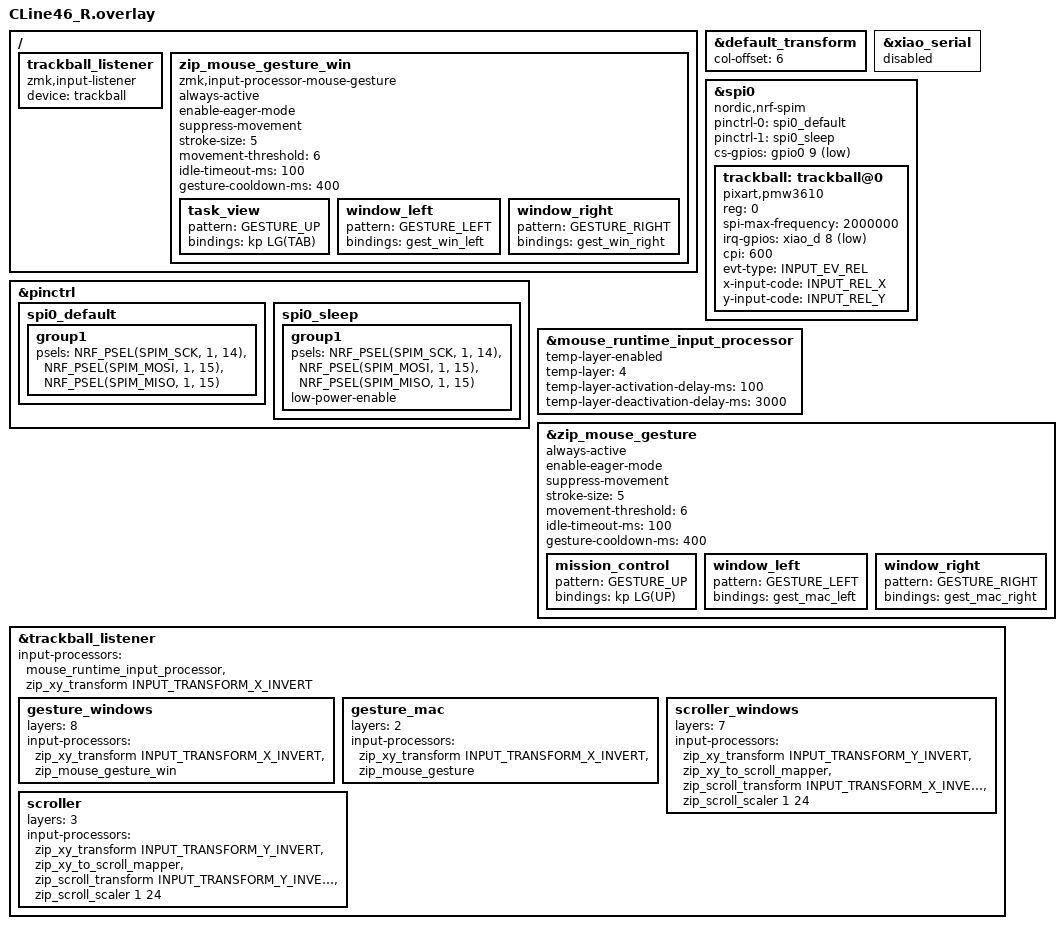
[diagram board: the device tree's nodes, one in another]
#include "CLine46.dtsi"
#include <zephyr/dt-bindings/input/input-event-codes.h>
#include <input/processors.dtsi>
#include <input/processors/runtime-input-processor.dtsi>
#include <behaviors/battery_history_request.dtsi>
#include <mouse-gesture.dtsi>
#include <dt-bindings/zmk/mouse-gesture.h>
#include <dt-bindings/zmk/keys.h>

&default_transform {
    col-offset = <6>;
};


/ {
    trackball_listener {
        status = "okay";
        compatible = "zmk,input-listener";
        device = <&trackball>;
    };
};

&pinctrl {
    spi0_default: spi0_default {
        group1 {
            psels = <NRF_PSEL(SPIM_SCK, 1, 14)>,
                <NRF_PSEL(SPIM_MOSI, 1, 15)>,
                <NRF_PSEL(SPIM_MISO, 1, 15)>;
        };
    };

    spi0_sleep: spi0_sleep {
        group1 {
            psels = <NRF_PSEL(SPIM_SCK, 1, 14)>,
                <NRF_PSEL(SPIM_MOSI, 1, 15)>,
                <NRF_PSEL(SPIM_MISO, 1, 15)>;
            low-power-enable;
        };
    };
};


&xiao_serial { status = "disabled"; };

&spi0 {
    status = "okay";
    compatible = "nordic,nrf-spim";
    pinctrl-0 = <&spi0_default>;
    pinctrl-1 = <&spi0_sleep>;
    pinctrl-names = "default", "sleep";
    cs-gpios = <&gpio0 9 GPIO_ACTIVE_LOW>;  //P0.09を指定(CS)

    trackball: trackball@0 {
        status = "okay";
        compatible = "pixart,pmw3610";
        reg = <0>;
        spi-max-frequency = <2000000>;
        irq-gpios = <&xiao_d 8 (GPIO_ACTIVE_LOW | GPIO_PULL_UP)>;
        cpi = <600>;
        //swap-xy;
        evt-type = <INPUT_EV_REL>;
        x-input-code = <INPUT_REL_X>;
        y-input-code = <INPUT_REL_Y>;
    };
};

// オートマウスレイヤー（AML）の初期値。本体に保存された値（DYA Studio 等で変えたもの）があればそちらが優先される。
// settings_reset 後もこの値に戻るよう、2026-10-12 に本体の値（レイヤー4・100ms・3000ms）をそのまま書いた。
// 3000ms は DYA Studio のスライダー上限（2000ms）を超えるので、DYA で保存すると下がる点に注意。
&mouse_runtime_input_processor {
    temp-layer-enabled;
    temp-layer = <4>;
    temp-layer-activation-delay-ms = <100>;
    temp-layer-deactivation-delay-ms = <3000>;
};

// ジェスチャ（左親指4を押している間だけ。ボールの動きはカーソルに送らない）
// 共通: 動きと一致した瞬間に実行（eager）。続けて反応しないよう 400ms 待つ。数値の出発点は moNa2（Arai-yt）の設定
// Mac（レイヤー2）: 上＝Mission Control（Mac では CLine46 の Win キーが Control になるので LG）、左右＝ウィンドウ半分、Ctrl＋左右＝モニター移動
&zip_mouse_gesture {
    always-active;
    enable-eager-mode;
    suppress-movement;
    stroke-size = <5>;
    movement-threshold = <6>;
    idle-timeout-ms = <100>;
    gesture-cooldown-ms = <400>;

    mission_control { pattern = <GESTURE_UP>;    bindings = <&kp LG(UP)>; };
    window_left     { pattern = <GESTURE_LEFT>;  bindings = <&gest_mac_left>; };
    window_right    { pattern = <GESTURE_RIGHT>; bindings = <&gest_mac_right>; };
};

/ {
    // Windows（レイヤー8＝左親指4＋Windows モード）: 上＝タスクビュー、左右＝ウィンドウ半分、Ctrl＋左右＝モニター移動
    zip_mouse_gesture_win: zip_mouse_gesture_win {
        compatible = "zmk,input-processor-mouse-gesture";
        #input-processor-cells = <0>;
        always-active;
        enable-eager-mode;
        suppress-movement;
        stroke-size = <5>;
        movement-threshold = <6>;
        idle-timeout-ms = <100>;
        gesture-cooldown-ms = <400>;

        task_view    { pattern = <GESTURE_UP>;    bindings = <&kp LG(TAB)>; };
        window_left  { pattern = <GESTURE_LEFT>;  bindings = <&gest_win_left>; };
        window_right { pattern = <GESTURE_RIGHT>; bindings = <&gest_win_right>; };
    };
};

// Overrides for the input listener node
&trackball_listener {
    status = "okay";
    input-processors =<&mouse_runtime_input_processor>,
        //<&zip_xy_transform INPUT_TRANSFORM_Y_INVERT>;         //Y軸反転
        //<&zip_xy_transform INPUT_TRANSFORM_XY_SWAP>,        //X軸とY軸の入れ替え
        <&zip_xy_transform INPUT_TRANSFORM_X_INVERT>;       //X軸反転
        //<&zip_temp_layer 2 1000>;                            //オートマウスレイヤーの選択;


    // ジェスチャ。Windows 用（レイヤー8）を Mac 用（レイヤー2）より前に置く（レイヤー8 のときはレイヤー2 も有効なため）。
    // ボールの左右は生の値だと逆なので、カーソルと同じく X 軸を反転してから判定する。
    gesture_windows {
        layers = <8>;
        input-processors =
            <&zip_xy_transform INPUT_TRANSFORM_X_INVERT>,
            <&zip_mouse_gesture_win>;
    };

    gesture_mac {
        layers = <2>;
        input-processors =
            <&zip_xy_transform INPUT_TRANSFORM_X_INVERT>,
            <&zip_mouse_gesture>;
    };

    // Windows モード中のスクロール（レイヤー7＝スクロールキー＋Windows モード）。
    // Mac 用（下の scroller）と比べて上下・左右とも逆。上にある設定が先に使われるので、必ず scroller より前に置く。
    scroller_windows {
        layers = <7>;
        input-processors =
            <&zip_xy_transform INPUT_TRANSFORM_Y_INVERT>,       //Y軸反転
            <&zip_xy_to_scroll_mapper>,                         //スクロールモードに変更
            <&zip_scroll_transform INPUT_TRANSFORM_X_INVERT>,   //スクロールのX軸反転（Mac 用と逆）
            // スクロールのY軸反転は付けない（Mac 用と逆）
            <&zip_scroll_scaler 1 24>;                          //スクロール量を1/24倍（Mac 用と同じ）
    };

    scroller {
        layers = <3>;
        input-processors = 
            // <&zip_xy_transform INPUT_TRANSFORM_XY_SWAP>,        //X軸とY軸の入れ替え
            // <&zip_xy_transform INPUT_TRANSFORM_X_INVERT>,       //X軸反転
            <&zip_xy_transform INPUT_TRANSFORM_Y_INVERT>,       //Y軸反転
            <&zip_xy_to_scroll_mapper>,                         //スクロールモードに変更
            // <&zip_scroll_transform INPUT_TRANSFORM_X_INVERT>, //スクロールのX軸反転
            <&zip_scroll_transform INPUT_TRANSFORM_Y_INVERT>,   //スクロールのY軸反転
            <&zip_scroll_scaler 1 24>;                          //スクロール量を1/24倍
    };
};
